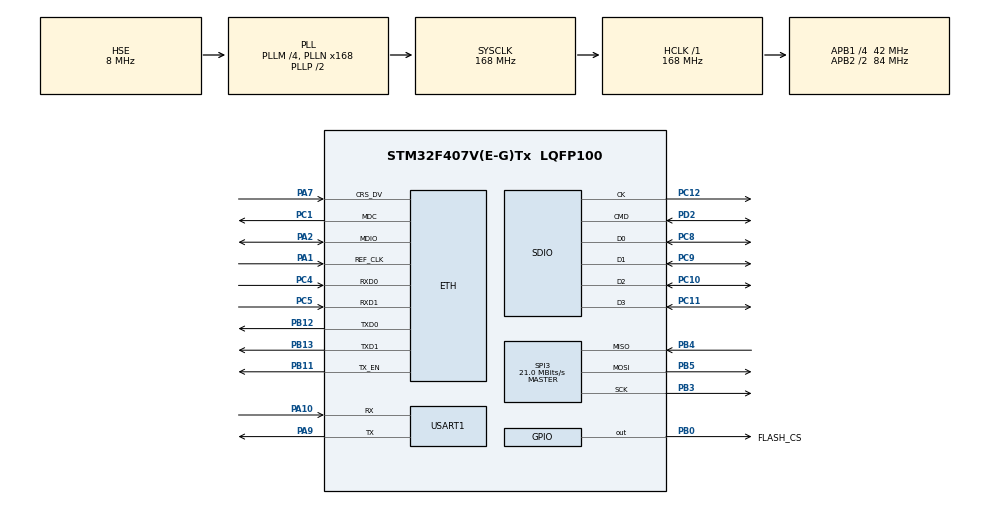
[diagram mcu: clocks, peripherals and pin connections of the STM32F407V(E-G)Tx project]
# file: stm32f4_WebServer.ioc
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Dma.Request0=USART1_TX
Dma.Request1=SDIO_RX
Dma.Request2=SDIO_TX
Dma.Request3=SPI3_RX
Dma.Request4=SPI3_TX
Dma.SDIO_RX.1.Direction=DMA_PERIPH_TO_MEMORY
Dma.SDIO_RX.1.FIFOMode=DMA_FIFOMODE_ENABLE
Dma.SDIO_RX.1.FIFOThreshold=DMA_FIFO_THRESHOLD_FULL
Dma.SDIO_RX.1.Instance=DMA2_Stream3
Dma.SDIO_RX.1.MemBurst=DMA_MBURST_INC4
Dma.SDIO_RX.1.MemDataAlignment=DMA_MDATAALIGN_WORD
Dma.SDIO_RX.1.MemInc=DMA_MINC_ENABLE
Dma.SDIO_RX.1.Mode=DMA_PFCTRL
Dma.SDIO_RX.1.PeriphBurst=DMA_PBURST_INC4
Dma.SDIO_RX.1.PeriphDataAlignment=DMA_PDATAALIGN_WORD
Dma.SDIO_RX.1.PeriphInc=DMA_PINC_DISABLE
Dma.SDIO_RX.1.Priority=DMA_PRIORITY_LOW
Dma.SDIO_TX.2.Direction=DMA_MEMORY_TO_PERIPH
Dma.SDIO_TX.2.FIFOMode=DMA_FIFOMODE_ENABLE
Dma.SDIO_TX.2.FIFOThreshold=DMA_FIFO_THRESHOLD_FULL
Dma.SDIO_TX.2.Instance=DMA2_Stream6
Dma.SDIO_TX.2.MemBurst=DMA_MBURST_INC4
Dma.SDIO_TX.2.MemDataAlignment=DMA_MDATAALIGN_WORD
Dma.SDIO_TX.2.MemInc=DMA_MINC_ENABLE
Dma.SDIO_TX.2.Mode=DMA_PFCTRL
Dma.SDIO_TX.2.PeriphBurst=DMA_PBURST_INC4
Dma.SDIO_TX.2.PeriphDataAlignment=DMA_PDATAALIGN_WORD
Dma.SDIO_TX.2.PeriphInc=DMA_PINC_DISABLE
Dma.SDIO_TX.2.Priority=DMA_PRIORITY_LOW
Dma.SPI3_RX.3.Direction=DMA_PERIPH_TO_MEMORY
Dma.SPI3_RX.3.FIFOMode=DMA_FIFOMODE_DISABLE
Dma.SPI3_RX.3.Instance=DMA1_Stream0
Dma.SPI3_RX.3.MemDataAlignment=DMA_MDATAALIGN_BYTE
Dma.SPI3_RX.3.MemInc=DMA_MINC_ENABLE
Dma.SPI3_RX.3.Mode=DMA_NORMAL
Dma.SPI3_RX.3.PeriphDataAlignment=DMA_PDATAALIGN_BYTE
Dma.SPI3_RX.3.PeriphInc=DMA_PINC_DISABLE
Dma.SPI3_RX.3.Priority=DMA_PRIORITY_LOW
Dma.SPI3_TX.4.Direction=DMA_MEMORY_TO_PERIPH
Dma.SPI3_TX.4.FIFOMode=DMA_FIFOMODE_ENABLE
Dma.SPI3_TX.4.FIFOThreshold=DMA_FIFO_THRESHOLD_FULL
Dma.SPI3_TX.4.Instance=DMA1_Stream5
Dma.SPI3_TX.4.MemBurst=DMA_MBURST_SINGLE
Dma.SPI3_TX.4.MemDataAlignment=DMA_MDATAALIGN_BYTE
Dma.SPI3_TX.4.MemInc=DMA_MINC_ENABLE
Dma.SPI3_TX.4.Mode=DMA_NORMAL
Dma.SPI3_TX.4.PeriphBurst=DMA_PBURST_SINGLE
Dma.SPI3_TX.4.PeriphDataAlignment=DMA_PDATAALIGN_BYTE
Dma.SPI3_TX.4.PeriphInc=DMA_PINC_DISABLE
Dma.SPI3_TX.4.Priority=DMA_PRIORITY_LOW
Dma.USART1_TX.0.Direction=DMA_MEMORY_TO_PERIPH
Dma.USART1_TX.0.FIFOMode=DMA_FIFOMODE_DISABLE
Dma.USART1_TX.0.Instance=DMA2_Stream7
Dma.USART1_TX.0.MemDataAlignment=DMA_MDATAALIGN_BYTE
Dma.USART1_TX.0.MemInc=DMA_MINC_ENABLE
Dma.USART1_TX.0.Mode=DMA_CIRCULAR
Dma.USART1_TX.0.PeriphDataAlignment=DMA_PDATAALIGN_BYTE
Dma.USART1_TX.0.PeriphInc=DMA_PINC_DISABLE
Dma.USART1_TX.0.Priority=DMA_PRIORITY_LOW
ETH.MediaInterface=ETH_MEDIA_INTERFACE_RMII
ETH.PHY_DUPLEX_STATUS=0x0010
ETH.PHY_Name_RMII=LAN8742A_PHY_ADDRESS
ETH.PHY_SPEED_STATUS=0x0004
ETH.PHY_SR=0x1F
ETH.PhyAddress=1
FATFS._FS_LOCK=1
FATFS._FS_RPATH=0
FATFS._MAX_SS=4096
FATFS._USE_LFN=2
FATFS._USE_MUTEX=0
FREERTOS.Tasks01=defaultTask,24,256,StartDefaultTask,Default,NULL,Dynamic,NULL,NULL
FREERTOS.configENABLE_FPU=1
FREERTOS.configUSE_NEWLIB_REENTRANT=1
LWIP.DEFAULT_THREAD_STACKSIZE=2048
LWIP.LWIP_HTTPD=1
LWIP.LWIP_HTTPD_CGI=1
LWIP.LWIP_HTTPD_CUSTOM_FILES=1
LWIP.LWIP_HTTPD_DYNAMIC_FILE_READ=1
LWIP.LWIP_HTTPD_DYNAMIC_HEADERS=1
LWIP.LWIP_HTTPD_FS_ASYNC_READ=0
LWIP.LWIP_HTTPD_SSI_INCLUDE_TAG=0
LWIP.LWIP_HTTPD_SUPPORT_POST=1
LWIP.MEMP_NUM_TCP_PCB=5
LWIP.MEMP_NUM_UDP_PCB=4
LWIP.MEM_SIZE=1024*10
LWIP.TCPIP_THREAD_STACKSIZE=2048
LWIP.Version=v2.1.2_Cube
Mcu.Family=STM32F4
Mcu.Name=STM32F407V(E-G)Tx
Mcu.Package=LQFP100
NVIC.DMA1_Stream0_IRQn=true\:5\:0\:false\:false\:true\:true\:false\:true
NVIC.DMA1_Stream5_IRQn=true\:5\:0\:false\:false\:true\:true\:false\:true
NVIC.DMA2_Stream3_IRQn=true\:5\:0\:false\:false\:true\:true\:false\:true
NVIC.DMA2_Stream6_IRQn=true\:5\:0\:false\:false\:true\:true\:false\:true
NVIC.DMA2_Stream7_IRQn=true\:5\:0\:false\:false\:true\:true\:false\:true
NVIC.ETH_IRQn=true\:5\:0\:false\:false\:true\:true\:false\:true
NVIC.PriorityGroup=NVIC_PRIORITYGROUP_4
NVIC.SDIO_IRQn=true\:5\:0\:false\:false\:true\:true\:true\:true
NVIC.TIM1_UP_TIM10_IRQn=true\:15\:0\:false\:false\:true\:false\:false\:true
NVIC.TimeBase=TIM1_UP_TIM10_IRQn
NVIC.TimeBaseIP=TIM1
PA1.Mode=RMII
PA1.Signal=ETH_REF_CLK
PA10.Mode=Asynchronous
PA10.Signal=USART1_RX
PA13.Mode=Serial_Wire
PA13.Signal=SYS_JTMS-SWDIO
PA14.Mode=Serial_Wire
PA14.Signal=SYS_JTCK-SWCLK
PA2.Mode=RMII
PA2.Signal=ETH_MDIO
PA7.Mode=RMII
PA7.Signal=ETH_CRS_DV
PA9.Mode=Asynchronous
PA9.Signal=USART1_TX
PB0.GPIO_Label=FLASH_CS
PB0.Signal=GPIO_Output
PB11.Mode=RMII
PB11.Signal=ETH_TX_EN
PB12.Mode=RMII
PB12.Signal=ETH_TXD0
PB13.Mode=RMII
PB13.Signal=ETH_TXD1
PB3.Mode=Full_Duplex_Master
PB3.Signal=SPI3_SCK
PB4.Mode=Full_Duplex_Master
PB4.Signal=SPI3_MISO
PB5.Mode=Full_Duplex_Master
PB5.Signal=SPI3_MOSI
PC1.Mode=RMII
PC1.Signal=ETH_MDC
PC10.GPIO_PuPd=GPIO_PULLUP
PC10.Mode=SD_4_bits_Wide_bus
PC10.Signal=SDIO_D2
PC11.GPIO_PuPd=GPIO_PULLUP
PC11.Mode=SD_4_bits_Wide_bus
PC11.Signal=SDIO_D3
PC12.GPIO_PuPd=GPIO_NOPULL
PC12.Mode=SD_4_bits_Wide_bus
PC12.Signal=SDIO_CK
PC4.Mode=RMII
PC4.Signal=ETH_RXD0
PC5.Mode=RMII
PC5.Signal=ETH_RXD1
PC8.GPIO_PuPd=GPIO_PULLUP
PC8.Mode=SD_4_bits_Wide_bus
PC8.Signal=SDIO_D0
PC9.GPIO_PuPd=GPIO_PULLUP
PC9.Mode=SD_4_bits_Wide_bus
PC9.Signal=SDIO_D1
PD2.GPIO_PuPd=GPIO_PULLUP
PD2.Mode=SD_4_bits_Wide_bus
PD2.Signal=SDIO_CMD
PH0-OSC_IN.Mode=HSE-External-Oscillator
PH0-OSC_IN.Signal=RCC_OSC_IN
PH1-OSC_OUT.Mode=HSE-External-Oscillator
PH1-OSC_OUT.Signal=RCC_OSC_OUT
ProjectManager.HeapSize=0x400
ProjectManager.StackSize=0x800
ProjectManager.TargetToolchain=STM32CubeIDE
RCC.48MHZClocksFreq_Value=48000000
RCC.AHBFreq_Value=168000000
RCC.APB1CLKDivider=RCC_HCLK_DIV4
RCC.APB1Freq_Value=42000000
RCC.APB1TimFreq_Value=84000000
RCC.APB2CLKDivider=RCC_HCLK_DIV2
RCC.APB2Freq_Value=84000000
RCC.APB2TimFreq_Value=168000000
RCC.CortexFreq_Value=168000000
RCC.HCLKFreq_Value=168000000
RCC.HSE_VALUE=8000000
RCC.HSI_VALUE=16000000
RCC.LSE_VALUE=32768
RCC.PLLM=4
RCC.PLLN=168
RCC.PLLQ=7
RCC.PLLSourceVirtual=RCC_PLLSOURCE_HSE
RCC.RCC_RTC_Clock_SourceVirtual=RCC_RTCCLKSOURCE_LSE
RCC.RCC_RTC_Clock_Source_FROM_HSE=RCC_RTCCLKSOURCE_HSE_DIV8
RCC.SYSCLKFreq_VALUE=168000000
RCC.SYSCLKSource=RCC_SYSCLKSOURCE_PLLCLK
RCC.VCOOutputFreq_Value=336000000
SDIO.ClockDiv=4
SPI3.CalculateBaudRate=21.0 MBits/s
SPI3.Direction=SPI_DIRECTION_2LINES
SPI3.Mode=SPI_MODE_MASTER
SPI3.VirtualType=VM_MASTER
USART1.VirtualMode=VM_ASYNC
VP_FATFS_VS_SDIO.Mode=SDIO
VP_FREERTOS_VS_CMSIS_V2.Mode=CMSIS_V2
VP_LWIP_VS_Enabled.Mode=Enabled
VP_SYS_VS_tim1.Mode=TIM1
board=custom

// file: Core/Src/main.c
/* USER CODE BEGIN Header */
/**
  ******************************************************************************
  * @file           : main.c
  * @brief          : Main program body
  ******************************************************************************
  * @attention
  *
  * <h2><center>&copy; Copyright (c) 2023 STMicroelectronics.
  * All rights reserved.</center></h2>
  *
  * This software component is licensed by ST under Ultimate Liberty license
  * SLA0044, the "License"; You may not use this file except in compliance with
  * the License. You may obtain a copy of the License at:
  *                             www.st.com/SLA0044
  *
  ******************************************************************************
  */
/* USER CODE END Header */
#include "main.h"
#include "cmsis_os.h"
#include "dma.h"
#include "fatfs.h"
#include "lwip.h"
#include "sdio.h"
#include "spi.h"
#include "usart.h"
#include "gpio.h"

/* USER CODE BEGIN Includes */
#include "w25qxx.h"
#include "storage.h"
/* USER CODE END Includes */

void SystemClock_Config(void);
void MX_FREERTOS_Init(void);

int main(void)
{

  /* MCU Configuration--------------------------------------------------------*/

  /* Reset of all peripherals, Initializes the Flash interface and the Systick. */
  HAL_Init();

  /* Configure the system clock */
  SystemClock_Config();

  /* Initialize all configured peripherals */
  MX_GPIO_Init();
  MX_SDIO_SD_Init();
  MX_FATFS_Init();
  MX_DMA_Init();
  MX_USART1_UART_Init();
  MX_SPI3_Init();
  /* USER CODE BEGIN 2 */
  W25qxx_Init();
  init_storage();
  /* USER CODE END 2 */

  /* Init scheduler */
  osKernelInitialize();  /* Call init function for freertos objects (in freertos.c) */
  MX_FREERTOS_Init();
  /* Start scheduler */
  osKernelStart();

  /* We should never get here as control is now taken by the scheduler */
  /* Infinite loop */
  while (1)
  {

  }
}

void SystemClock_Config(void)
{
  RCC_OscInitTypeDef RCC_OscInitStruct = {0};
  RCC_ClkInitTypeDef RCC_ClkInitStruct = {0};

  /** Configure the main internal regulator output voltage
  */
  __HAL_RCC_PWR_CLK_ENABLE();
  __HAL_PWR_VOLTAGESCALING_CONFIG(PWR_REGULATOR_VOLTAGE_SCALE1);
  /** Initializes the RCC Oscillators according to the specified parameters
  * in the RCC_OscInitTypeDef structure.
  */
  RCC_OscInitStruct.OscillatorType = RCC_OSCILLATORTYPE_HSE;
  RCC_OscInitStruct.HSEState = RCC_HSE_ON;
  RCC_OscInitStruct.PLL.PLLState = RCC_PLL_ON;
  RCC_OscInitStruct.PLL.PLLSource = RCC_PLLSOURCE_HSE;
  RCC_OscInitStruct.PLL.PLLM = 4;
  RCC_OscInitStruct.PLL.PLLN = 168;
  RCC_OscInitStruct.PLL.PLLP = RCC_PLLP_DIV2;
  RCC_OscInitStruct.PLL.PLLQ = 7;
  if (HAL_RCC_OscConfig(&RCC_OscInitStruct) != HAL_OK)
  {
    Error_Handler();
  }
  /** Initializes the CPU, AHB and APB buses clocks
  */
  RCC_ClkInitStruct.ClockType = RCC_CLOCKTYPE_HCLK|RCC_CLOCKTYPE_SYSCLK
                              |RCC_CLOCKTYPE_PCLK1|RCC_CLOCKTYPE_PCLK2;
  RCC_ClkInitStruct.SYSCLKSource = RCC_SYSCLKSOURCE_PLLCLK;
  RCC_ClkInitStruct.AHBCLKDivider = RCC_SYSCLK_DIV1;
  RCC_ClkInitStruct.APB1CLKDivider = RCC_HCLK_DIV4;
  RCC_ClkInitStruct.APB2CLKDivider = RCC_HCLK_DIV2;

  if (HAL_RCC_ClockConfig(&RCC_ClkInitStruct, FLASH_LATENCY_5) != HAL_OK)
  {
    Error_Handler();
  }
}

void HAL_TIM_PeriodElapsedCallback(TIM_HandleTypeDef *htim)
{
  if (htim->Instance == TIM1) {
    HAL_IncTick();
  }
}

void Error_Handler(void)
{
  __disable_irq();
  while (1)
  {
  }
}

/************************ (C) COPYRIGHT STMicroelectronics *****END OF FILE****/

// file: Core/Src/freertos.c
/* USER CODE BEGIN Header */
/**
  ******************************************************************************
  * File Name          : freertos.c
  * Description        : Code for freertos applications
  ******************************************************************************
  * @attention
  *
  * <h2><center>&copy; Copyright (c) 2023 STMicroelectronics.
  * All rights reserved.</center></h2>
  *
  * This software component is licensed by ST under Ultimate Liberty license
  * SLA0044, the "License"; You may not use this file except in compliance with
  * the License. You may obtain a copy of the License at:
  *                             www.st.com/SLA0044
  *
  ******************************************************************************
  */
/* USER CODE END Header */

#include "FreeRTOS.h"
#include "task.h"
#include "main.h"
#include "cmsis_os.h"

/* USER CODE BEGIN Includes */
#include "httpd.h"
#include "w25qxx.h"
/* USER CODE END Includes */

/* Definitions for defaultTask */
osThreadId_t defaultTaskHandle;
const osThreadAttr_t defaultTask_attributes = {
  .name = "defaultTask",
  .stack_size = 512 * 4,
  .priority = (osPriority_t) osPriorityNormal,
};

void StartDefaultTask(void *argument);

extern void MX_LWIP_Init(void);
void MX_FREERTOS_Init(void); /* (MISRA C 2004 rule 8.1) */

void MX_FREERTOS_Init(void) {

  /* Create the thread(s) */
  /* creation of defaultTask */
  defaultTaskHandle = osThreadNew(StartDefaultTask, NULL, &defaultTask_attributes);

}

void StartDefaultTask(void *argument)
{
  /* init code for LWIP */
  MX_LWIP_Init();
  /* USER CODE BEGIN StartDefaultTask */
  httpd_init();

  /* Infinite loop */
  for(;;)
  {
    osDelay(1);
  }
  /* USER CODE END StartDefaultTask */
}

/************************ (C) COPYRIGHT STMicroelectronics *****END OF FILE****/
